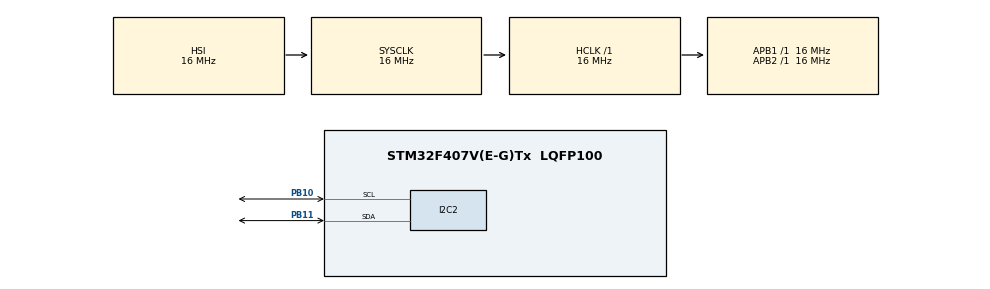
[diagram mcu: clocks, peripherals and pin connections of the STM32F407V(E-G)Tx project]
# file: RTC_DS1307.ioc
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Mcu.Family=STM32F4
Mcu.Name=STM32F407V(E-G)Tx
Mcu.Package=LQFP100
NVIC.PriorityGroup=NVIC_PRIORITYGROUP_0
PB10.GPIO_Pu=GPIO_PULLUP
PB10.Mode=I2C
PB10.Signal=I2C2_SCL
PB11.GPIO_Pu=GPIO_PULLUP
PB11.Mode=I2C
PB11.Signal=I2C2_SDA
ProjectManager.HeapSize=0x200
ProjectManager.StackSize=0x400
ProjectManager.TargetToolchain=STM32CubeIDE
RCC.48MHZClocksFreq_Value=14285714.285714285
RCC.AHBFreq_Value=16000000
RCC.APB1Freq_Value=16000000
RCC.APB1TimFreq_Value=16000000
RCC.APB2Freq_Value=16000000
RCC.APB2TimFreq_Value=16000000
RCC.CortexFreq_Value=16000000
RCC.HCLKFreq_Value=16000000
RCC.HSE_VALUE=8000000
RCC.HSI_VALUE=16000000
RCC.LSE_VALUE=32768
RCC.PLLM=8
RCC.PLLN=50
RCC.PLLP=RCC_PLLP_DIV4
RCC.PLLQ=7
RCC.SYSCLKFreq_VALUE=16000000
RCC.VCOOutputFreq_Value=100000000
board=STM32F407G-DISC1

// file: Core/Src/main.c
/* USER CODE BEGIN Header */
/**
  ******************************************************************************
  * @file           : main.c
  * @brief          : Main program body
  ******************************************************************************
  * @attention
  *
  * Copyright (c) 2023 STMicroelectronics.
  * All rights reserved.
  *
  * This software is licensed under terms that can be found in the LICENSE file
  * in the root directory of this software component.
  * If no LICENSE file comes with this software, it is provided AS-IS.
  *
  ******************************************************************************
  */
/* USER CODE END Header */
#include "main.h"

/* USER CODE BEGIN Includes */
#include "rtc.h"
#include <stdio.h>
/* USER CODE END Includes */

I2C_HandleTypeDef hi2c2;

void SystemClock_Config(void);
static void MX_GPIO_Init(void);
static void MX_I2C2_Init(void);

/* USER CODE BEGIN 0 */

/*************************************************************************************
 * @fn									- number_to_string
 *
 * @brief								- This function converts an integer value into its corresponding character.
 *
 * @param[in]  num						- Integer value.
 *
 * @param[in]  buf						- Character.
 */

void number_to_string(uint8_t num, char *buf){
	if (num < 10){
		buf[0] = '0';
		buf[1] = num+48;
	}else if (num >= 10 && num <99){
		buf[0] = (num / 10) + 48;
		buf[1] = (num % 10) + 48;
	}
}

/*************************************************************************************
 * @fn									- time_to_string
 *
 * @brief								- This function converts the rtc_time struct into a string.
 *
 * @param[in]  rtc_time					- Time handler.
 *
 * @return     char*					- Returned string in this format: hh:mm:ss.
 */

char *time_to_string(RTC_time_t *rtc_time){
	static char buf[9];
	buf[2] = ':';
	buf[5] = ':';

	number_to_string(rtc_time->hours, buf);
	number_to_string(rtc_time->minutes, &buf[3]);
	number_to_string(rtc_time->seconds, &buf[6]);

	buf[8] = '\0';

	return buf;
}

/*************************************************************************************
 * @fn									- date_to_string
 *
 * @brief								- This function converts the rtc_date struct into a string.
 *
 * @param[in]  rtc_date					- Date handler.
 *
 * @return     char*					- Returned string in this format: dd/mm/20yy.
 */

//
char *date_to_string(RTC_date_t *rtc_date){
	static char buf[11];
	buf[2] = '/';
	buf[5] = '/';
	buf[6] = '2';
	buf[7] = '0';

	number_to_string(rtc_date->date, buf);
	number_to_string(rtc_date->month, &buf[3]);
	number_to_string(rtc_date->year, &buf[8]);

	buf[10] = '\0';

	return buf;
}

/* USER CODE END 0 */

int main(void)
{

  /* MCU Configuration--------------------------------------------------------*/

  /* Reset of all peripherals, Initializes the Flash interface and the Systick. */
  HAL_Init();

  /* Configure the system clock */
  SystemClock_Config();

  /* Initialize all configured peripherals */
  MX_GPIO_Init();
  MX_I2C2_Init();
  /* USER CODE BEGIN 2 */

  RTC_HandleTypeDef rtc;
  RTC_time_t current_time;
  RTC_date_t current_date;

  if (rtc_init(&rtc, &hi2c2)){
	printf("RTC init has failed\n");
	while(1);
  }

  current_date.day = SUNDAY;
  current_date.date = 31;
  current_date.month = 12;
  current_date.year = 15;

  current_time.hours = 11;
  current_time.minutes = 59;
  current_time.seconds = 41;
  current_time.time_format = TIME_FORMAT_12HRS_PM;

  rtc_set_current_time(&rtc, &current_time);
  rtc_set_current_date(&rtc, &current_date);

  /* USER CODE END 2 */

  /* Infinite loop */
  /* USER CODE BEGIN WHILE */
  while (1)
  {
	  rtc_get_current_date(&rtc, &current_date);
	  rtc_get_current_time(&rtc, &current_time);

	  char *am_pm;
	  if (current_time.time_format != TIME_FORMAT_24HRS){
	  	am_pm = (current_time.time_format) ? "PM" : "AM";
	  	printf("Current time = %s %s\n", time_to_string(&current_time), am_pm); // 04:25:41 PM
	  }else {
		  printf("Current_time = %s\n", time_to_string(&current_time)); // 04:25:41
	  }

	  printf("Current date: %s <%s>\n", date_to_string(&current_date), DAY_OF_WEEK(current_date.day));
	  HAL_Delay(1000);
    /* USER CODE END WHILE */

  }
}

void SystemClock_Config(void)
{
  RCC_OscInitTypeDef RCC_OscInitStruct = {0};
  RCC_ClkInitTypeDef RCC_ClkInitStruct = {0};

  /** Configure the main internal regulator output voltage
  */
  __HAL_RCC_PWR_CLK_ENABLE();
  __HAL_PWR_VOLTAGESCALING_CONFIG(PWR_REGULATOR_VOLTAGE_SCALE1);

  /** Initializes the RCC Oscillators according to the specified parameters
  * in the RCC_OscInitTypeDef structure.
  */
  RCC_OscInitStruct.OscillatorType = RCC_OSCILLATORTYPE_HSI;
  RCC_OscInitStruct.HSIState = RCC_HSI_ON;
  RCC_OscInitStruct.HSICalibrationValue = RCC_HSICALIBRATION_DEFAULT;
  RCC_OscInitStruct.PLL.PLLState = RCC_PLL_NONE;
  if (HAL_RCC_OscConfig(&RCC_OscInitStruct) != HAL_OK)
  {
    Error_Handler();
  }

  /** Initializes the CPU, AHB and APB buses clocks
  */
  RCC_ClkInitStruct.ClockType = RCC_CLOCKTYPE_HCLK|RCC_CLOCKTYPE_SYSCLK
                              |RCC_CLOCKTYPE_PCLK1|RCC_CLOCKTYPE_PCLK2;
  RCC_ClkInitStruct.SYSCLKSource = RCC_SYSCLKSOURCE_HSI;
  RCC_ClkInitStruct.AHBCLKDivider = RCC_SYSCLK_DIV1;
  RCC_ClkInitStruct.APB1CLKDivider = RCC_HCLK_DIV1;
  RCC_ClkInitStruct.APB2CLKDivider = RCC_HCLK_DIV1;

  if (HAL_RCC_ClockConfig(&RCC_ClkInitStruct, FLASH_LATENCY_0) != HAL_OK)
  {
    Error_Handler();
  }
}

static void MX_I2C2_Init(void)
{

  hi2c2.Instance = I2C2;
  hi2c2.Init.ClockSpeed = 100000;
  hi2c2.Init.DutyCycle = I2C_DUTYCYCLE_2;
  hi2c2.Init.OwnAddress1 = 0;
  hi2c2.Init.AddressingMode = I2C_ADDRESSINGMODE_7BIT;
  hi2c2.Init.DualAddressMode = I2C_DUALADDRESS_DISABLE;
  hi2c2.Init.OwnAddress2 = 0;
  hi2c2.Init.GeneralCallMode = I2C_GENERALCALL_DISABLE;
  hi2c2.Init.NoStretchMode = I2C_NOSTRETCH_DISABLE;
  if (HAL_I2C_Init(&hi2c2) != HAL_OK)
  {
    Error_Handler();
  }

}

static void MX_GPIO_Init(void)
{

  /* GPIO Ports Clock Enable */
  __HAL_RCC_GPIOB_CLK_ENABLE();

}

void Error_Handler(void)
{
  __disable_irq();
  while (1)
  {
  }
}
